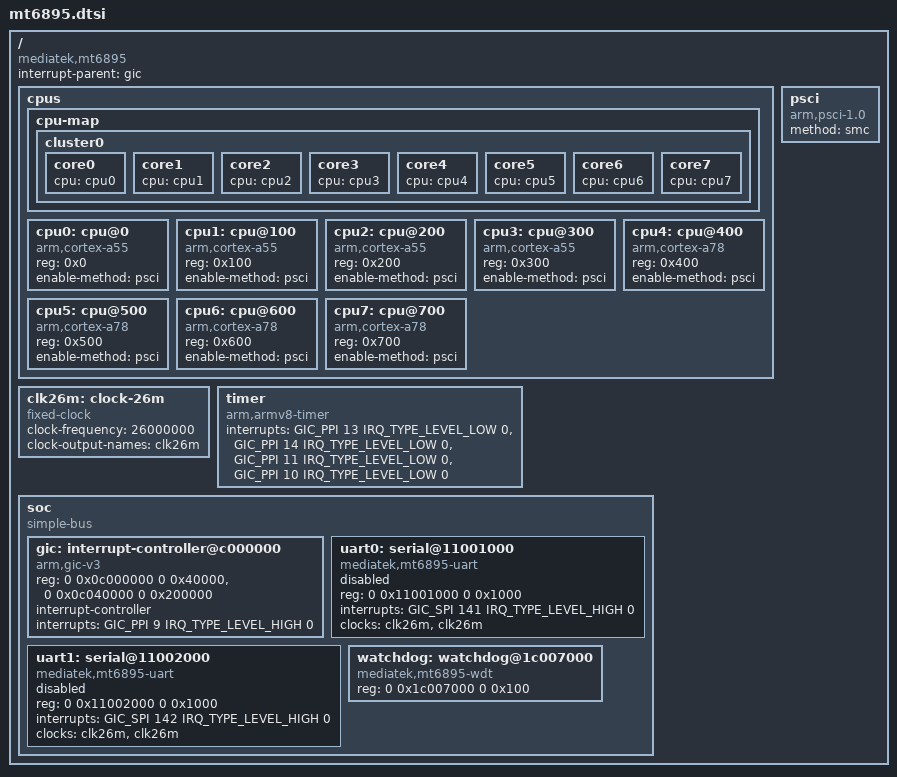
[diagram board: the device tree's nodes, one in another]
// SPDX-License-Identifier: (GPL-2.0 OR MIT)

#include <dt-bindings/interrupt-controller/arm-gic.h>

/ {
	compatible = "mediatek,mt6895";
	interrupt-parent = <&gic>;
	#address-cells = <2>;
	#size-cells = <2>;

	cpus {
		#address-cells = <1>;
		#size-cells = <0>;

		cpu-map {
			cluster0 {
				core0 {
					cpu = <&cpu0>;
				};

				core1 {
					cpu = <&cpu1>;
				};

				core2 {
					cpu = <&cpu2>;
				};

				core3 {
					cpu = <&cpu3>;
				};

				core4 {
					cpu = <&cpu4>;
				};

				core5 {
					cpu = <&cpu5>;
				};

				core6 {
					cpu = <&cpu6>;
				};

				core7 {
					cpu = <&cpu7>;
				};
			};
		};

		cpu0: cpu@0 {
			device_type = "cpu";
			compatible = "arm,cortex-a55";
			reg = <0x0>;
			enable-method = "psci";
		};

		cpu1: cpu@100 {
			device_type = "cpu";
			compatible = "arm,cortex-a55";
			reg = <0x100>;
			enable-method = "psci";
		};

		cpu2: cpu@200 {
			device_type = "cpu";
			compatible = "arm,cortex-a55";
			reg = <0x200>;
			enable-method = "psci";
		};

		cpu3: cpu@300 {
			device_type = "cpu";
			compatible = "arm,cortex-a55";
			reg = <0x300>;
			enable-method = "psci";
		};

		cpu4: cpu@400 {
			device_type = "cpu";
			compatible = "arm,cortex-a78";
			reg = <0x400>;
			enable-method = "psci";
		};

		cpu5: cpu@500 {
			device_type = "cpu";
			compatible = "arm,cortex-a78";
			reg = <0x500>;
			enable-method = "psci";
		};

		cpu6: cpu@600 {
			device_type = "cpu";
			compatible = "arm,cortex-a78";
			reg = <0x600>;
			enable-method = "psci";
		};

		cpu7: cpu@700 {
			device_type = "cpu";
			compatible = "arm,cortex-a78";
			reg = <0x700>;
			enable-method = "psci";
		};
	};

	clk26m: clock-26m {
		compatible = "fixed-clock";
		#clock-cells = <0>;
		clock-frequency = <26000000>;
		clock-output-names = "clk26m";
	};

	psci {
		compatible = "arm,psci-1.0";
		method = "smc";
	};

	timer {
		compatible = "arm,armv8-timer";
		interrupts = <GIC_PPI 13 IRQ_TYPE_LEVEL_LOW 0>,
			     <GIC_PPI 14 IRQ_TYPE_LEVEL_LOW 0>,
			     <GIC_PPI 11 IRQ_TYPE_LEVEL_LOW 0>,
			     <GIC_PPI 10 IRQ_TYPE_LEVEL_LOW 0>;
	};

	soc {
		compatible = "simple-bus";
		ranges;
		#address-cells = <2>;
		#size-cells = <2>;

		gic: interrupt-controller@c000000 {
			compatible = "arm,gic-v3";
			reg = <0 0x0c000000 0 0x40000>,
			      <0 0x0c040000 0 0x200000>;
			#interrupt-cells = <4>;
			interrupt-controller;
			interrupts = <GIC_PPI 9 IRQ_TYPE_LEVEL_HIGH 0>;
		};

		uart0: serial@11001000 {
			compatible = "mediatek,mt6895-uart", "mediatek,mt6577-uart";
			reg = <0 0x11001000 0 0x1000>;
			interrupts = <GIC_SPI 141 IRQ_TYPE_LEVEL_HIGH 0>;
			clocks = <&clk26m>, <&clk26m>;
			clock-names = "baud", "bus";
			status = "disabled";
		};

		uart1: serial@11002000 {
			compatible = "mediatek,mt6895-uart", "mediatek,mt6577-uart";
			reg = <0 0x11002000 0 0x1000>;
			interrupts = <GIC_SPI 142 IRQ_TYPE_LEVEL_HIGH 0>;
			clocks = <&clk26m>, <&clk26m>;
			clock-names = "baud", "bus";
			status = "disabled";
		};

		watchdog: watchdog@1c007000 {
			compatible = "mediatek,mt6895-wdt", "mediatek,mt6589-wdt";
			reg = <0 0x1c007000 0 0x100>;
		};
	};
};
